# STM32L4P5 register map
File version: 1.8
CPU: CM4 r0p1, little endian, MPU, FPU, 4 interrupt priority bits
Registers are 32-bit, read-write, reset 0x0 unless marked. A register's access mark holds for its fields unless they carry their own. Offsets are from the block's base; [hi:lo] are bit positions; lines under a group give offsets from that group; {n}, {i} and the like mark numbered series; 'fields as' and 'values as' point back to an identical list.

## ADC1 — Analog-to-Digital Converter
Base 0x50040000
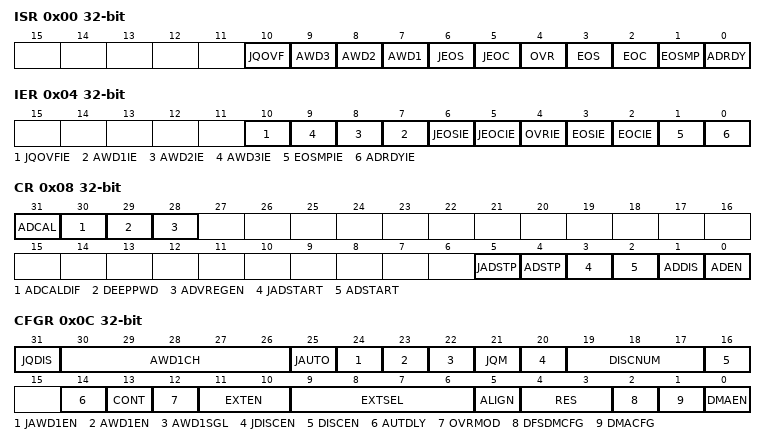
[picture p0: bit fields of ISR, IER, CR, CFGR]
0x00 ISR — interrupt and status register
  [10] JQOVF write-1-clears
    on read: 0=NoOverflow (No injected context queue overflow has occurred); 1=Overflow (Injected context queue overflow has occurred) | on write: 1=Clear injected context queue overflow flag
  [n+6] AWD{n} (n=1..3) write-1-clears — Analog watchdog {n} flag
    on read: 0=NoEvent (No analog watchdog event occurred); 1=Event (Analog watchdog event occurred) | on write: 1=Clear analog watchdog event occurred flag
  [6] JEOS write-1-clears
    on read: 0=NotComplete (Injected sequence is not complete); 1=Complete (Injected sequence complete) | on write: 1=Clear Injected sequence complete flag
  [5] JEOC write-1-clears
    on read: 0=NotComplete (Injected conversion is not complete); 1=Complete (Injected conversion complete) | on write: 1=Clear injected conversion complete flag
  [4] OVR write-1-clears
    on read: 0=No overrun occurred; 1=Overrun occurred | on write: 1=Clear overrun occurred flag
  [3] EOS write-1-clears
    on read: 0=NotComplete (Regular sequence is not complete); 1=Complete (Regular sequence complete) | on write: 1=Clear regular sequence complete flag
  [2] EOC write-1-clears
    on read: 0=NotComplete (Regular conversion is not complete); 1=Complete (Regular conversion complete) | on write: 1=Clear regular conversion complete flag
  [1] EOSMP write-1-clears
    on read: 0=NotEnded (End of sampling phase no yet reached); 1=Ended (End of sampling phase reached) | on write: 1=Clear end of sampling phase reached flag
  [0] ADRDY write-1-clears
    on read: 0=NotReady (ADC is not ready to start conversion); 1=Ready (ADC is ready to start conversion) | on write: 1=Clear ADC is ready to start conversion flag
0x04 IER — interrupt enable register
  [10] JQOVFIE
    0=Disabled (Injected context queue overflow interrupt disabled); 1=Enabled (Injected context queue overflow interrupt enabled)
  [n+6] AWD{n}IE (n=1..3) — Analog watchdog {n} interrupt enable
    0=Disabled (Analog watchdog interrupt disabled); 1=Enabled (Analog watchdog interrupt enabled)
  [6] JEOSIE
    0=Disabled (End of injected sequence interrupt disabled); 1=Enabled (End of injected sequence interrupt enabled)
  [5] JEOCIE
    0=Disabled (End of injected conversion interrupt disabled); 1=Enabled (End of injected conversion interrupt enabled)
  [4] OVRIE
    0=Disabled (Overrun interrupt disabled); 1=Enabled (Overrun interrupt enabled)
  [3] EOSIE
    0=Disabled (End of regular sequence interrupt disabled); 1=Enabled (End of regular sequence interrupt enabled)
  [2] EOCIE
    0=Disabled (End of regular conversion interrupt disabled); 1=Enabled (End of regular conversion interrupt enabled)
  [1] EOSMPIE
    0=Disabled (End of regular conversion sampling phase interrupt disabled); 1=Enabled (End of regular conversion sampling phase interrupt enabled)
  [0] ADRDYIE
    0=Disabled (ADC ready interrupt disabled); 1=Enabled (ADC ready interrupt enabled)
0x08 CR — control register
  [31] ADCAL write-1-sets
    on read: 0=NotCalibrating (ADC calibration either not yet performed or completed); 1=Calibrating (ADC calibration in progress) | on write: 1=StartCalibration (Start the ADC calibration sequence)
  [30] ADCALDIF
    0=SingleEnded (Calibration for single-ended mode); 1=Differential (Calibration for differential mode)
  [29] DEEPPWD
    0=NotDeepPowerDown (ADC not in Deep-power down); 1=DeepPowerDown (ADC in Deep-power-down (default reset state))
  [28] ADVREGEN
    0=Disabled (ADC Voltage regulator disabled); 1=Enabled (ADC Voltage regulator enabled)
  [5] JADSTP write-1-sets
    on read: 0=NotStopping (No stop command active); 1=Stopping (ADC stopping conversion) | on write: 1=StopConversion (Stop the active conversion)
  [4] ADSTP write-1-sets
    values as JADSTP
  [3] JADSTART write-1-sets
    on read: 0=NotActive (No conversion ongoing); 1=Active (ADC operating and may be converting) | on write: 1=StartConversion (Start the ADC conversion (may be delayed for hardware triggers))
  [2] ADSTART write-1-sets
    values as JADSTART
  [1] ADDIS write-1-sets
    on read: 0=NotDisabling (No disable command active); 1=Disabling (ADC disabling) | on write: 1=Disable the ADC
  [0] ADEN write-1-sets
    on read: 0=Disabled (ADC disabled); 1=Enabled (ADC enabled) | on write: 1=Enabled (Enable the ADC)
0x0C CFGR — configuration register
  [31] JQDIS — Injected Queue disable
  [30:26] AWD1CH range 0..18 — AWDCH1CH
  [25] JAUTO
    0=Disabled (Automatic injected group conversion disabled); 1=Enabled (Automatic injected group conversion enabled)
  [24] JAWD1EN
    0=Disabled (Analog watchdog 1 disabled on injected channels); 1=Enabled (Analog watchdog 1 enabled on injected channels)
  [23] AWD1EN
    0=Disabled (Analog watchdog 1 disabled on regular channels); 1=Enabled (Analog watchdog 1 enabled on regular channels)
  [22] AWD1SGL
    0=All (Analog watchdog 1 enabled on all channels); 1=Single (Analog watchdog 1 enabled on single channel selected in AWD1CH)
  [21] JQM
    0=Mode0 (JSQR Mode 0: Queue maintains the last written configuration into JSQR); 1=Mode1 (JSQR Mode 1: An empty queue disables software and hardware triggers of the injected sequence)
  [20] JDISCEN
    0=Disabled (Discontinuous mode on injected channels disabled); 1=Enabled (Discontinuous mode on injected channels enabled)
  [19:17] DISCNUM
  [16] DISCEN
    0=Disabled (Discontinuous mode on regular channels disabled); 1=Enabled (Discontinuous mode on regular channels enabled)
  [14] AUTDLY
    0=Off (Auto delayed conversion mode off); 1=On (Auto delayed conversion mode on)
  [13] CONT
    0=Single conversion mode; 1=Continuous conversion mode
  [12] OVRMOD
    0=Preserve DR register when an overrun is detected; 1=Overwrite DR register when an overrun is detected
  [11:10] EXTEN
    0=Disabled (Trigger detection disabled); 1=RisingEdge (Trigger detection on the rising edge); 2=FallingEdge (Trigger detection on the falling edge); 3=BothEdges (Trigger detection on both the rising and falling edges)
  [9:6] EXTSEL — EXTSEL3
    0=TIM1_CC1 (Timer 1 CC1 event); 1=TIM1_CC2 (Timer 1 CC2 event); 2=TIM1_CC3 (Timer 1 CC3 event); 3=TIM2_CC2 (Timer 2 CC2 event); 4=TIM3_TRGO (Timer 3 TRGO event); 6=EXTI11 (EXTI line 11); 9=TIM1_TRGO (Timer 1 TRGO event); 10=TIM1_TRGO2 (Timer 1 TRGO2 event); 11=TIM2_TRGO (Timer 2 TRGO event); 13=TIM6_TRGO (Timer 6 TRGO event); 14=TIM15_TRGO (Timer 15 TRGO event); 15=TIM3_CC4 (Timer 3 CC4 event)
  [5] ALIGN
    0=Right alignment; 1=Left alignment
  [4:3] RES
    0=Bits12 (12-bit); 1=Bits10 (10-bit); 2=Bits8 (8-bit); 3=Bits6 (6-bit)
  [2] DFSDMCFG — DFSDM mode configuration
  [1] DMACFG
    0=OneShot (DMA One Shot mode selected); 1=Circular (DMA Circular mode selected)
  [0] DMAEN
    0=Disabled (DMA disabled); 1=Enabled (DMA enabled)
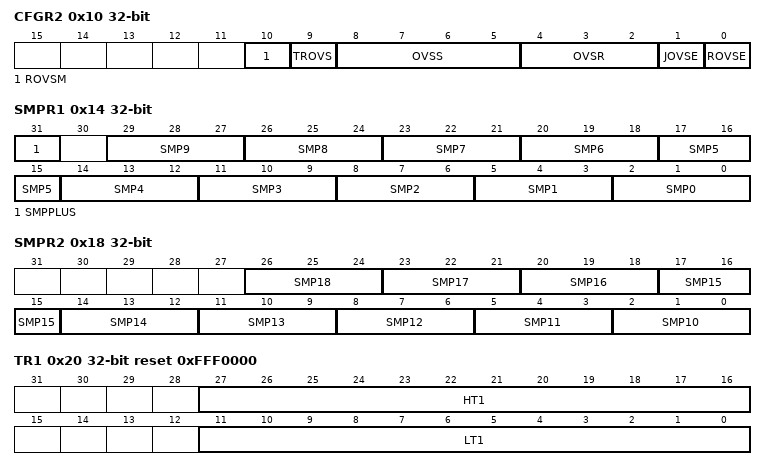
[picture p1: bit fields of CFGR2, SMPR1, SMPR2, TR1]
0x10 CFGR2 — configuration register
  [10] ROVSM — Regular Oversampling mode
    0=ContinuedMode (When injected conversions are triggered, the oversampling is temporary stopped and continued after the injection sequence (oversampling buffer is maintained during injected sequence)); 1=ResumedMode (When injected conversions are triggered, the current oversampling is aborted and resumed from start after the injection sequence (oversampling buffer is zeroed by injected sequence start))
  [9] TROVS — Triggered Regular Oversampling
    0=All (All oversampled conversions for a channel are done consecutively following a trigger); 1=Single (Each oversampled conversion for a channel needs a new trigger)
  [8:5] OVSS — ALIGN
    0=NoShift; {v}=Shift{v}Bit (v=1..8)
  [4:2] OVSR — RES
    0=Ratio2 (2x); 1=Ratio4 (4x); 2=Ratio8 (8x); 3=Ratio16 (16x); 4=Ratio32 (32x); 5=Ratio64 (64x); 6=Ratio128 (128x); 7=Ratio256 (256x)
  [1] JOVSE — DMACFG
    0=Disabled (Injected Oversampling disabled); 1=Enabled (Injected Oversampling enabled)
  [0] ROVSE — DMAEN
    0=Disabled (Regular Oversampling disabled); 1=Enabled (Regular Oversampling enabled)
0x14 SMPR1 — sample time register 1
  [31] SMPPLUS — Addition of one clock cycle to the sampling time
    0=KeepCycles (The sampling time remains set to 2.5 ADC clock cycles remains); 1=Add1Cycle (2.5 ADC clock cycle sampling time becomes 3.5 ADC clock cycles for the ADC_SMPR1 and ADC_SMPR2 registers)
  [3n+2:3n] SMP{n} (n=0..9) — Channel {n} sample time selection
    0=Cycles2_5 (2.5 ADC clock cycles); 1=Cycles6_5 (6.5 ADC clock cycles); 2=Cycles12_5 (12.5 ADC clock cycles); 3=Cycles24_5 (24.5 ADC clock cycles); 4=Cycles47_5 (47.5 ADC clock cycles); 5=Cycles92_5 (92.5 ADC clock cycles); 6=Cycles247_5 (247.5 ADC clock cycles); 7=Cycles640_5 (640.5 ADC clock cycles)
0x18 SMPR2 — sample time register 2
  [3n-28:3n-30] SMP{n} (n=10..18) — Channel {n} sample time selection
    values as SMPR1.SMP0
0x20 TR1 reset 0xFFF0000 — watchdog threshold register 1
  [27:16] HT1, [11:0] LT1
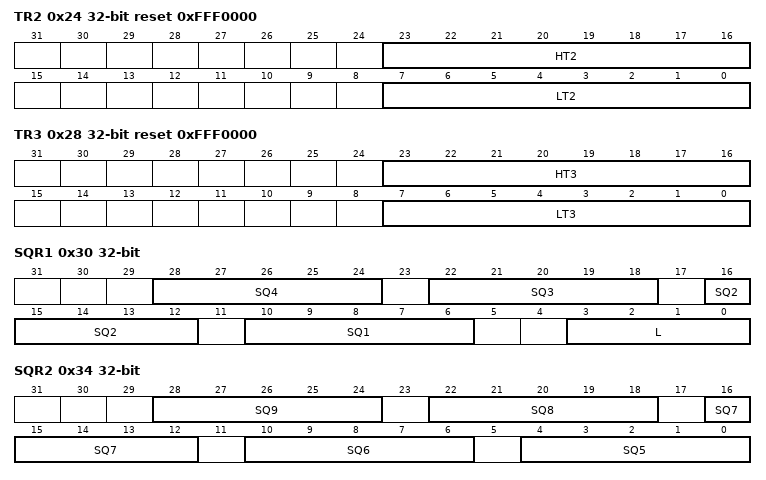
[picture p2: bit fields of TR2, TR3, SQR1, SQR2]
0x24 TR2 reset 0xFFF0000 — watchdog threshold register
  [23:16] HT2, [7:0] LT2
0x28 TR3 reset 0xFFF0000 — watchdog threshold register 3
  [23:16] HT3, [7:0] LT3
0x30 SQR1 — regular sequence register 1
  [6n+4:6n] SQ{n} (n=1..4) range 0..18 — {n} conversion in regular sequence
  [3:0] L — Regular channel sequence length
0x34 SQR2 — regular sequence register 2
  [6n-26:6n-30] SQ{n} (n=5..9) range 0..18 — {n} conversion in regular sequence
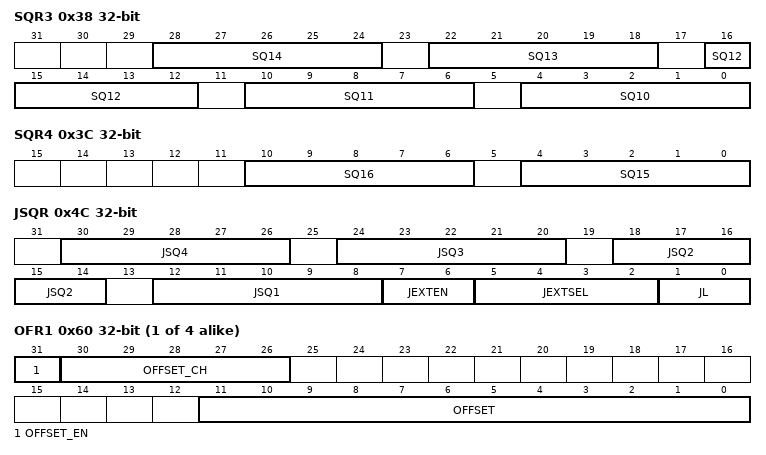
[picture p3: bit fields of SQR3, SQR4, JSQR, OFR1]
0x38 SQR3 — regular sequence register 3
  [6n-56:6n-60] SQ{n} (n=10..14) range 0..18 — {n} conversion in regular sequence
0x3C SQR4 — regular sequence register 4
  [6n-86:6n-90] SQ{n} (n=15..16) range 0..18 — {n} conversion in regular sequence
0x40 DR ro — regular Data Register
  [15:0] RDATA — Regular Data converted
0x4C JSQR — injected sequence register
  [6n+6:6n+2] JSQ{n} (n=1..4) range 0..19 — {n} conversion in injected sequence
  [7:6] JEXTEN
    values as CFGR.EXTEN
  [5:2] JEXTSEL
    0=TIM1_TRGO (Timer 1 TRGO event); 1=TIM1_CC4 (Timer 1 CC4 event); 2=TIM2_TRGO (Timer 2 TRGO event); 3=TIM2_CC1 (Timer 2 CC1 event); 4=TIM3_CC4 (Timer 3 CC4 event); 6=EXTI15 (EXTI line 15); 8=TIM1_TRGO2 (Timer 1 TRGO2 event); 11=TIM3_CC3 (Timer 3 CC3 event); 12=TIM3_TRGO (Timer 3 TRGO event); 13=TIM3_CC1 (Timer 3 CC1 event); 14=TIM6_TRGO (Timer 6 TRGO event); 15=TIM15_TRGO (Timer 15 TRGO event)
  [1:0] JL
{0x5C+4i} OFR{i} (i=1..4) — offset register {i}
  [31] OFFSET_EN — Offset X Enable
    0=Disabled (This bit is written by software to enable or disable the offset programmed into bits OFFSETy[11:0]); 1=Enabled (This bit is written by software to enable or disable the offset programmed into bits OFFSETy[11:0])
  [30:26] OFFSET_CH — Channel selection for the data offset X
  [11:0] OFFSET — Data offset X for the channel programmed into bits OFFSET_CH
{0x7C+4i} JDR{i} (i=1..4) ro — injected data register {i}
  [15:0] JDATA — Injected data
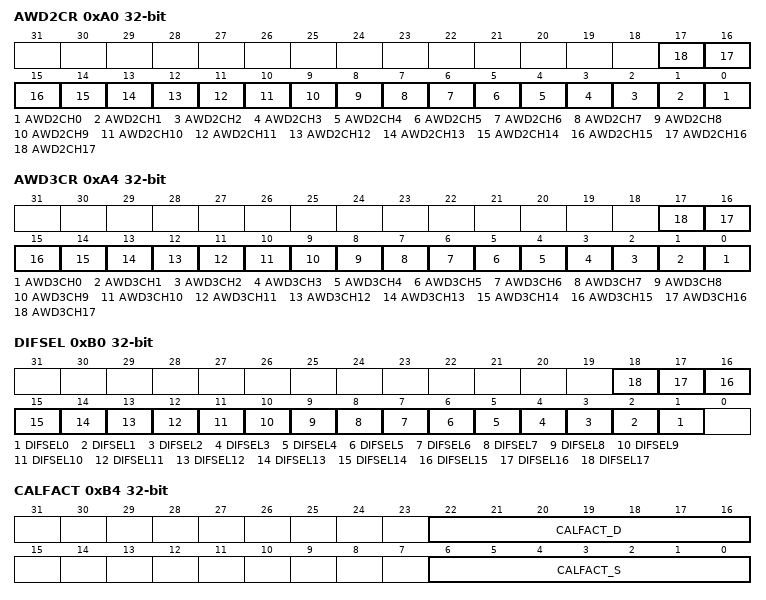
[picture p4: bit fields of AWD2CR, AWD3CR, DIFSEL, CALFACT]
0xA0 AWD2CR — Analog Watchdog 2 Configuration Register
  [n] AWD2CH{n} (n=0..17)
    0=NotMonitored (Input channel not monitored by AWDx); 1=Monitored (Input channel monitored by AWDx)
0xA4 AWD3CR — Analog Watchdog 3 Configuration Register
  [n] AWD3CH{n} (n=0..17)
    values as AWD2CR.AWD2CH0
0xB0 DIFSEL access not given — Differential Mode Selection Register 2
  [n+1] DIFSEL{n} (n=0..17) — Differential mode for channel {n}
    0=SingleEnded (Input channel is configured in single-ended mode); 1=Differential (Input channel is configured in differential mode)
0xB4 CALFACT — Calibration Factors
  [22:16] CALFACT_D, [6:0] CALFACT_S
